# T113-S3 register map
Vendor: Allwinner; Series: T113-S3; File version: 0.1
CPU: other 0, little endian, MPU, no FPU, 0 interrupt priority bits
Registers are 32-bit, read-write, reset 0x0 unless marked. A register's access mark holds for its fields unless they carry their own. Offsets are from the block's base; [hi:lo] are bit positions; lines under a group give offsets from that group; {n}, {i} and the like mark numbered series; 'fields as' and 'values as' point back to an identical list.

## PWM
Base 0x02000C00
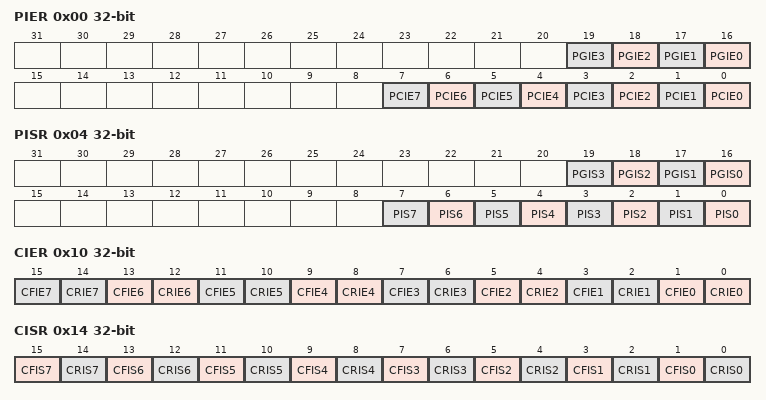
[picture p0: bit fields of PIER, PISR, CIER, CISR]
0x00 PIER — PWM IRQ Enable Register
  [n+16] PGIE{n} (n=0..3) — PWM Group {n} Interrupt Enable 0: Disable 1: Enable
    0=Disable; 1=Enable
  [n] PCIE{n} (n=0..7) — PWM Channel {n} Interrupt Enable 0: PWM Channel {n} Interrupt Disable 1: PWM Channel {n} Interrupt Enable
    0=PWM_Channel_{n}_Interrupt_Disable; 1=PWM_Channel_{n}_Interrupt_Enable
0x04 PISR — PWM IRQ Status Register
  [n+16] PGIS{n} write-1-clears (n=0..3) — PWM Group {n} Interrupt Status
  [n] PIS{n} write-1-clears (n=0..7) — PWM Channel {n} Interrupt Status When the PWM channel {n} counter reaches the Entire Cycle Value, this bit is set 1 by hardware. Writing 1 to clear this bit. Reads 0: PWM channel {n} interrupt is not pending. Reads 1: PWM channel {n} interrupt is pending. Writes 0: No effect. Writes 1: Clear PWM channel {n} interrupt status.
0x10 CIER — Capture IRQ Enable Register
  [2n+1] CFIE{n} (n=0..7) — If the enable bit is set to 1, when the capture channel {n} captures falling edge, it generates a capture channel {n} pending. 0: Capture channel {n} fall lock interrupt disable 1: Capture channel {n} fall lock interrupt enable
    0=Capture_channel_{n}_fall_lock_interrupt_disable; 1=Capture_channel_{n}_fall_lock_interrupt_enable
  [2n] CRIE{n} (n=0..7) — If the enable bit is set to 1, when the capture channel {n} captures rising edge, it generates a capture channel {n} pending. 0: Capture channel {n} rise lock interrupt disable 1: Capture channel {n} rise lock interrupt enable
    0=Capture_channel_{n}_rise_lock_interrupt_disable; 1=Capture_channel_{n}_rise_lock_interrupt_enable
0x14 CISR — Capture IRQ Status Register
  [15] CFIS7 write-1-clears — Status of the capture channel 7 falling lock interrupt When the capture channel 7 captures falling edge, if the fall lock interrupt ( ) is enabled, this bit is set to 1 by hardware. Writing 1 to clear this bit. Reads 0: The capture channel 7 interrupt is not pending. Reads 1: The capture channel 7 interrupt is pending. Writes 0: No effect. Writes 1: Clear the status of the capture channel 7 interrupt.
  [14] CRIS7 write-1-clears — Status of the capture channel 7 rising lock interrupt When the capture channel 7 captures rising edge, if the rise lock interrupt ( ) is enabled, this bit is set to 1 by hardware. Write 1 to clear this bit. Reads 0: The capture channel 7 interrupt is not pending. Reads 1: The capture channel 7 interrupt is pending. Writes 0: No effect. Writes 1: Clear the status of the capture channel 7 interrupt.
  [13] CFIS6 write-1-clears — Status of the capture channel 6 falling lock interrupt When the capture channel 6 captures falling edge, if the fall lock interrupt ( ) is enabled, this bit is set to 1 by hardware. Writing 1 to clear this bit. Reads 0: The capture channel 6 interrupt is not pending. Reads 1: The capture channel 6 interrupt is pending. Writes 0: No effect. Writes 1: Clear the status of the capture channel 6 interrupt.
  [12] CRIS6 write-1-clears — Status of the capture channel 6 rising lock interrupt. When the capture channel 6 captures rising edge, if the rise lock interrupt ( ) is enabled, this bit is set to 1 by hardware. Writing 1 to clear this bit. Reads 0: The capture channel 6 interrupt is not pending. Reads 1: The capture channel 6 interrupt is pending. Writes 0: No effect. Writes 1: Clear the status of the capture channel 6 interrupt.
  [11] CFIS5 write-1-clears — Status of the capture channel 5 falling lock interrupt When the capturing channel 5 captures falling edge, if the fall lock interrupt ( ) is enabled, this bit is set to 1 by hardware. Writing 1 to clear this bit. Reads 0: The capture channel 5 interrupt is not pending. Reads 1: The capture channel 5 interrupt is pending. Writes 0: No effect. Reads 1: Clear the status of the capture channel 5 interrupt.
  [10] CRIS5 write-1-clears — Status of the capture channel 5 rising lock interrupt When the capture channel 5 captures rising edge, if the rise lock interrupt ( ) is enabled, this bit is set to 1 by hardware. Writing 1 to clear this bit. Reads 0: The capture channel 5 interrupt is not pending. Reads 1: The capture channel 5 interrupt is pending. Writes 0: No effect. Writes 1: Clear the status of the capture channel 5 interrupt.
  [9] CFIS4 write-1-clears — Status of the capture channel 4 falling lock interrupt When the capture channel 4 captures falling edge, if the fall lock interrupt ( ) is enabled, this bit is set to 1 by hardware. Writing 1 to clear this bit. Reads 0: The capture channel 4 interrupt is not pending. Reads 1: The capture channel 4 interrupt is pending. Writes 0: No effect. Writes 1: Clear the status of the capture channel 4 interrupt.
  [8] CRIS4 write-1-clears — Status of the capture channel 4 rising lock interrupt. When the capture channel 4 captures rising edge, if the rise lock interrupt ( ) is enabled, this bit is set to 1 by hardware. Writing 1 to clear this bit. Reads 0: The capture channel 4 interrupt is not pending. Reads 1: The capture channel 4 interrupt is pending. Writes 0: No effect. Writes 1: Clear the status of the capture channel 4 interrupt status.
  [7] CFIS3 write-1-clears — Status of the capture channel 3 falling lock interrupt. When the capture channel 3 captures falling edge, if the fall lock interrupt ( ) is enabled, this bit is set to 1 by hardware. Writing 1 to clear this bit. Reads 0: The capture channel 3 interrupt is not pending. Reads 1: The capture channel 3 interrupt is pending. Writes 0: no effect. Writes 1: Clear the status of the capture channel 3 interrupt.
  [6] CRIS3 write-1-clears — Status of the capture channel 3 rising lock interrupt When the capture channel 3 captures rising edge, if the rise lock interrupt ( ) is enabled, this bit is set to 1 by hardware. Writing 1 to clear this bit. Reads 0: The capture channel 3 interrupt is not pending. Reads 1: The capture channel 3 interrupt is pending. Writes 0: no effect. Writes 1: Clear the status of the capture channel 3 interrupt.
  [5] CFIS2 write-1-clears — Status of the capture channel 2 falling lock interrupt When the capture channel 2 captures falling edge, if the fall lock interrupt ( ) is enabled, this bit is set to 1 by hardware. Writing 1 to clear this bit. Reads 0: The capture channel 2 interrupt is not pending. Reads 1: The capture channel 2 interrupt is pending. Writes 0: no effect. Writes 1: Clear the status of the capture channel 2 interrupt.
  [4] CRIS2 write-1-clears — Status of the capture channel 2 rising lock interrupt. When the capture channel 2 captures rising edge, if the rise lock interrupt ( ) is enabled, this bit is set to 1 by hardware. Writing 1 to clear this bit. Reads 0: The capture channel 2 interrupt is not pending. Reads 1: The capture channel 2 interrupt is pending. Writes 0: no effect. Writes 1: Clear the status of the capture channel 2 interrupt.
  [3] CFIS1 write-1-clears — Status of the capture channel 1 falling lock interrupt When the capture channel 1 captures falling edge, if the fall lock interrupt ( ) is enabled, this bit is set to 1 by hardware. Writing 1 to clear this bit. Reads 0: The capture channel 1 interrupt is not pending. Reads 1: The capture channel 1 interrupt is pending. Writes 0: no effect. Writes 1: Clear the status of the capture channel 1 interrupt.
  [2] CRIS1 write-1-clears — Status of the capture channel 1 rising lock interrupt. When the capture channel 1 captures rising edge, if the rise lock interrupt ( ) is enabled, this bit is set to 1 by hardware. Writing 1 to clear this bit. Reads 0: The capture channel 1 interrupt is not pending. Reads 1: The capture channel 1 interrupt is pending. Writes 0: no effect. Writes 1: Clear the status of the capture channel 1 interrupt.
  [1] CFIS0 write-1-clears — Status of the capture channel 0 falling lock interrupt When the capture channel 0 captures falling edge, if the fall lock interrupt ( ) is enabled, this bit is set to 1 by hardware. Writing 1 to clear this bit. Reads 0: The capture channel 0 interrupt is not pending. Reads 1: The capture channel 0 interrupt is pending. Writes 0: no effect. Writes 1: Clear the status of the capture channel 0 interrupt.
  [0] CRIS0 write-1-clears — Status of the capture channel 0 rising lock interrupt When the capture channel 0 captures rising edge, if the rise lock interrupt ( ) is enabled, this bit is set 1 by hardware. Writing 1 to clear this bit. Reads 0: The capture channel 0 interrupt is not pending. Reads 1: The capture channel 0 interrupt is pending. Writes 0: no effect. Writes 1: Clear the status of the capture channel 0 interrupt.
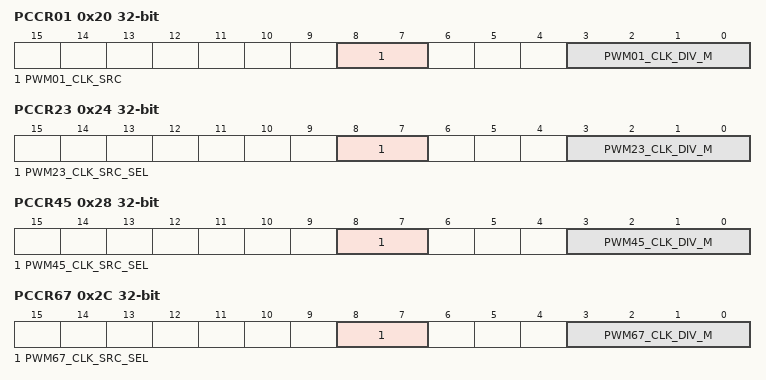
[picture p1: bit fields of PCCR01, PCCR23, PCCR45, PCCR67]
0x20 PCCR01 — PWM01 Clock Configuration Register
  [8:7] PWM01_CLK_SRC — Select PWM01 Clock Source 00: HOSC 01: APB0 Others: Reserved
    0=HOSC; 1=APB0
  [3:0] PWM01_CLK_DIV_M — PWM01 Clock Divide M 0000: /1 0001: /2 0010: /4 0011: /8 0100: /16 0101: /32 0110: /64 0111: /128 1000: /256 Others: Reserved
    0=_slash_1 (/1); 1=_slash_2 (/2); 2=_slash_4 (/4); 3=_slash_8 (/8); 4=_slash_16 (/16); 5=_slash_32 (/32); 6=_slash_64 (/64); 7=_slash_128 (/128); 8=_slash_256 (/256 Others: Reserved)
0x24 PCCR23 — PWM23 Clock Configuration Register
  [8:7] PWM23_CLK_SRC_SEL — Select PWM23 Clock Source 00: HOSC 01: APB0 Others: Reserved
    0=HOSC; 1=APB0 (APB0 Others: Reserved)
  [3:0] PWM23_CLK_DIV_M — PWM23 Clock Divide M 0000: /1 0001: /2 0010: /4 0011: /8 0100: /16 0101: /32 0110: /64 0111: /128 1000: /256 Others: Reserved
    values as PCCR01.PWM01_CLK_DIV_M
0x28 PCCR45 — PWM45 Clock Configuration Register
  [8:7] PWM45_CLK_SRC_SEL — Select PWM45 Clock Source 00: HOSC 01: APB0 Others: Reserved
    0=HOSC; 1=APB0 (APB0 Others: Reserved)
  [3:0] PWM45_CLK_DIV_M — PWM45 Clock Divide M 0000: /1 0001: /2 0010: /4 0011: /8 0100: /16 0101: /32 0110: /64 0111: /128 1000: /256 Others: Reserved
    values as PCCR01.PWM01_CLK_DIV_M
0x2C PCCR67 — PWM67 Clock Configuration Register
  [8:7] PWM67_CLK_SRC_SEL — Select PWM67 Clock Source 00: HOSC 01: APB0 Others: Reserved
    0=HOSC; 1=APB0 (APB0 Others: Reserved)
  [3:0] PWM67_CLK_DIV_M — PWM67 Clock Divide M 0000: /1 0001: /2 0010: /4 0011: /8 0100: /16 0101: /32 0110: /64 0111: /128 1000: /256 Others: Reserved
    values as PCCR01.PWM01_CLK_DIV_M
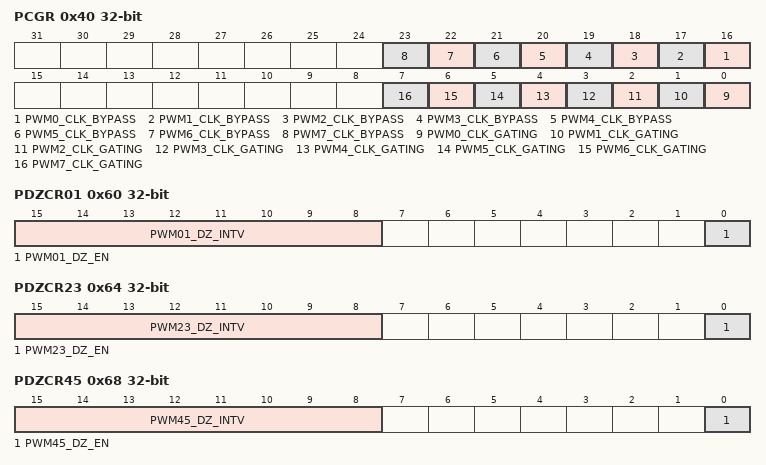
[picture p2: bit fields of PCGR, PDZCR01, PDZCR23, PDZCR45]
0x40 PCGR — PWM Clock Gating Register
  [n+16] PWM{n}_CLK_BYPASS (n=0..7) — Bypass clock source (after pre-scale) to PWM{n} output 0: not bypass 1: bypass
    0=not_bypass; 1=bypass
  [n] PWM{n}_CLK_GATING (n=0..7) — Gating clock for PWM{n} 0: Mask 1: Pass
    0=Mask; 1=Pass
0x60 PDZCR01 — PWM01 Dead Zone Control Register
  [15:8] PWM01_DZ_INTV — PWM01 Dead Zone Interval Value
  [0] PWM01_DZ_EN — PWM01 Dead Zone Enable 0: Dead Zone disable 1: Dead Zone enable
    0=Dead_Zone_disable; 1=Dead_Zone_enable
0x64 PDZCR23 — PWM23 Dead Zone Control Register
  [15:8] PWM23_DZ_INTV — PWM23 Dead Zone Interval Value
  [0] PWM23_DZ_EN — PWM23 Dead Zone Enable 0: Dead Zone disable 1: Dead Zone enable
    0=Dead_Zone_disable; 1=Dead_Zone_enable
0x68 PDZCR45 — PWM45 Dead Zone Control Register
  [15:8] PWM45_DZ_INTV — PWM45 Dead Zone Interval Value
  [0] PWM45_DZ_EN — PWM45 Dead Zone Enable 0: Dead Zone disable 1: Dead Zone enable
    0=Dead_Zone_disable; 1=Dead_Zone_enable
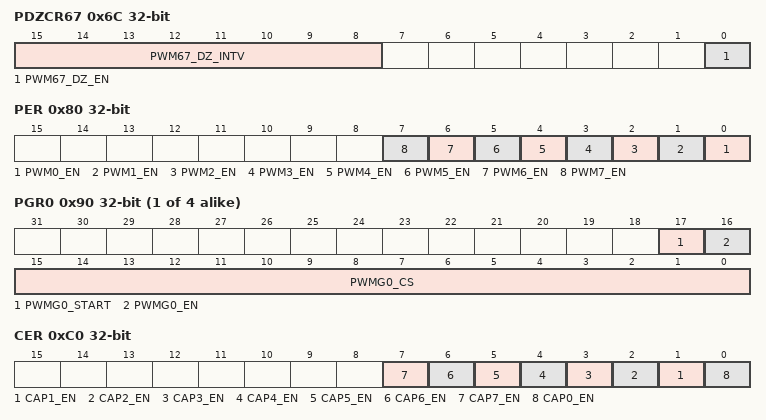
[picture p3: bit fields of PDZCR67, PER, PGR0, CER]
0x6C PDZCR67 — PWM67 Dead Zone Control Register
  [15:8] PWM67_DZ_INTV — PWM67 Dead Zone Interval Value
  [0] PWM67_DZ_EN — PWM67 Dead Zone Enable 0: Dead Zone disable 1: Dead Zone enable
    0=Dead_Zone_disable; 1=Dead_Zone_enable
0x80 PER — PWM Enable Register
  [all] fields
    0=PWM_disable; 1=PWM_enable
  [n] PWM{n}_EN (n=0..7) — When PWM is enabled, the 16-bit up-counter starts working and PWM channel{n} is permitted to output PWM waveform. 0: PWM disable 1: PWM enable
{0x90+4i} PGR{i} (i=0..3) — PWM Group{i} Register
  [17] PWMG{i}_START — The PWM channels selected in PWMG{i}_CS start to output PWM waveform at the same time.
  [16] PWMG{i}_EN — PWM Group{i} Enable.
  [15:0] PWMG{i}_CS — If bit[i] is set, the PWM i is selected as one channel of PWM Group{i}.
0xC0 CER — Capture Enable Register
  [all] fields
    0=Capture_disable; 1=Capture_enable
  [n] CAP{n}_EN (n=1..7) — When enabling the capture function, the 16-bit up-counter starts working, and the capture channel{n} is permitted to capture external falling edge or rising edge. 0: Capture disable 1: Capture enable
  [0] CAP0_EN — When enabling the capture function, the 16-bit up-counter starts working, and the capture channel is permitted to capture external falling edge or rising edge. 0: Capture disable 1: Capture enable
{0x104+0x20*i} _N[{i}] (i=0..7) group
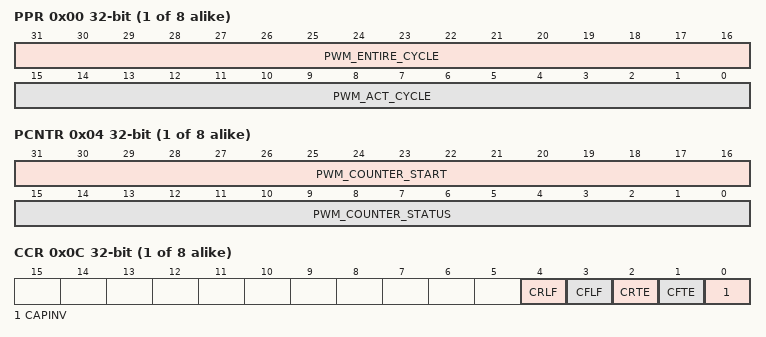
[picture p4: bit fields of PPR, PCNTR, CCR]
  0x00 PPR — (N= 0-7) PWM Period Register
    [31:16] PWM_ENTIRE_CYCLE — Number of the entire cycles in the PWM clock. 0: 1 cycle 1: 2 cycles ... N: N+1 cycles If the register needs to be modified dynamically, the PCLK should be faster than the PWM CLK.
    [15:0] PWM_ACT_CYCLE — Number of the active cycles in the PWM clock. 0: 0 cycle 1: 1 cycle ... N: N cycles
  0x04 PCNTR — (N= 0-7) PWM Count Register
    [31:16] PWM_COUNTER_START — PWM counter value is set for phase control.
    [15:0] PWM_COUNTER_STATUS ro — On PWM output or capture input, reading this register could get the current value of the PWM 16-bit up-counter.
  0x0C CCR — (N= 0-7) Capture Control Register
    [4] CRLF write-1-clears — When the capture channel captures a rising edge, the current value of the 16-bit up-counter is latched to CRLR, and then this bit is set 1 by hardware. Write 1 to clear this bit.
    [3] CFLF write-1-clears — When the capture channel captures a falling edge, the current value of the 16-bit up-counter is latched to CFLR, and then this bit is set 1 by hardware. Write 1 to clear this bit.
    [2] CRTE — Rising edge capture trigger enable
    [1] CFTE — Falling edge capture trigger enable
    [0] CAPINV — Inverse the signal input from capture channel before 16-bit counter of capture channel. 0: not inverse 1: inverse
      0=not_inverse; 1=inverse
  0x10 CRLR — (N= 0-7) Capture Rise Lock Register
    [15:0] CRLR ro — When the capture channel captures a rising edge, the current value of the 16-bit up-counter is latched to the register.
  0x14 CFLR — (N= 0-7) Capture Fall Lock Register
    [15:0] CFLR ro — When the capture channel captures a falling edge, the current value of the 16-bit up-counter is latched to the register.
